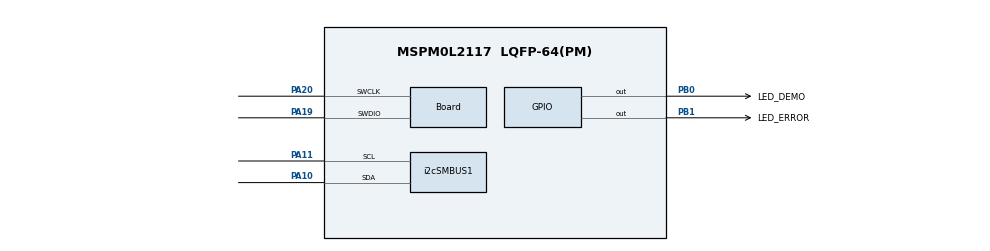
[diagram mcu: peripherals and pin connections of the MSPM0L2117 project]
 // @cliArgs --device "MSPM0L211X" --package "LQFP-64(PM)" --part "Default"
// @v2CliArgs --device "MSPM0L2117" --package "LQFP-64(PM)"
// @cliArgs --board /ti/boards/LP_MSPM0L2117 --rtos nortos

/**
 * Import the modules used in this configuration.
 */
const ADC12         = scripting.addModule("/ti/driverlib/ADC12", {}, false);
const ADC121        = ADC12.addInstance();
const Board         = scripting.addModule("/ti/driverlib/Board");
const GPIO          = scripting.addModule("/ti/driverlib/GPIO", {}, false);
const GPIO1         = GPIO.addInstance();
const TIMER         = scripting.addModule("/ti/driverlib/TIMER", {}, false);
const TIMER1        = TIMER.addInstance();
const i2cSMBUS      = scripting.addModule("/ti/driverlib/i2cSMBUS", {}, false);
const i2cSMBUS1     = i2cSMBUS.addInstance();
const ProjectConfig = scripting.addModule("/ti/project_config/ProjectConfig");

/**
 * Write custom configuration values to the imported modules.
 */
ADC121.$name                      = "SMB_ADC";
ADC121.adcMem0_name               = "SMB_ADC_channel_0";
ADC121.repeatMode                 = true;
ADC121.trigSrc                    = "DL_ADC12_TRIG_SRC_EVENT";
ADC121.enabledInterrupts          = ["DL_ADC12_INTERRUPT_MEM0_RESULT_LOADED"];
ADC121.adcMem0trig                = "DL_ADC12_TRIGGER_MODE_TRIGGER_NEXT";
ADC121.subChanID                  = 3;
ADC121.sampClkDiv                 = "DL_ADC12_CLOCK_DIVIDE_8";
ADC121.sampleTime0                = "25us";
ADC121.sampleTime1                = "12.5us";
ADC121.adcMem0chansel             = "DL_ADC12_INPUT_CHAN_7";
ADC121.peripheral.$assign         = "ADC0";
ADC121.peripheral.adcPin7.$assign = "PA22";

Board.peripheral.$assign          = "DEBUGSS";
Board.peripheral.swclkPin.$assign = "PA20";
Board.peripheral.swdioPin.$assign = "PA19";

GPIO1.$name                         = "SMB_GPIO";
GPIO1.associatedPins.create(2);
GPIO1.associatedPins[0].$name       = "LED_DEMO";
GPIO1.associatedPins[0].pin.$assign = "PB0";
GPIO1.associatedPins[1].$name       = "LED_ERROR";
GPIO1.associatedPins[1].pin.$assign = "PB1";

const SYSCTL              = scripting.addModule("/ti/driverlib/SYSCTL", {}, false);
SYSCTL.peripheral.$assign = "SYSCTL";

TIMER1.$name                       = "ADC_SAMPLE_TIMER";
TIMER1.timerMode                   = "PERIODIC";
TIMER1.timerPeriod                 = "10 ms";
TIMER1.timerClkDiv                 = 8;
TIMER1.event1ControllerInterruptEn = ["ZERO_EVENT"];
TIMER1.event1PublisherChannel      = 3;
TIMER1.timerStartTimer             = true;
TIMER1.timerClkSrc                 = "LFCLK";
TIMER1.peripheral.$assign          = "TIMG1";

i2cSMBUS1.$name                             = "SMB_I2C";
i2cSMBUS1.enableTimeoutA                    = true;
i2cSMBUS1.intGeneric                        = ["TIMEOUT_A"];
i2cSMBUS1.basicEnableTarget                 = true;
i2cSMBUS1.advTargetTXEmptyEn                = true;
i2cSMBUS1.basicTargetAddress                = 0x43;
i2cSMBUS1.intTarget                         = ["RXFIFO_TRIGGER","START","STOP","TXFIFO_EMPTY"];
i2cSMBUS1.timeoutACount                     = 135;
i2cSMBUS1.advTargetAckOverride              = true;
i2cSMBUS1.enableTargetPECACKNext            = true;
i2cSMBUS1.enableTargetPEC                   = true;
i2cSMBUS1.peripheral.$assign                = "UC7";
i2cSMBUS1.peripheral.sdaPin.$assign         = "PA10";
i2cSMBUS1.peripheral.sclPin.$assign         = "PA11";

ProjectConfig.genLibSMBUS        = true;
ProjectConfig.migrationCondition = true;
